# CRCP0_1.0 register map
Vendor: Texas Instruments
Peripheral module from a debugger description file (folder mspm0gx218_gx207).
Registers are 32-bit, read-write, no defined reset value unless marked. A register's access mark holds for its fields unless they carry their own. Offsets are as the file gives them; lines under a group give offsets from that group; [hi:lo] are bit positions; {n}, {i} and the like mark numbered series; 'fields as' and 'values as' point back to an identical list; <NAME> marks a mode.

## CRCP0
0x800 CRCP0_GPRCM group
  0x00 CRCP0_PWREN — Power enable
    [0] ENABLE — Enable the power
      0=DISABLE (Disable Power); 1=ENABLE (Enable Power)
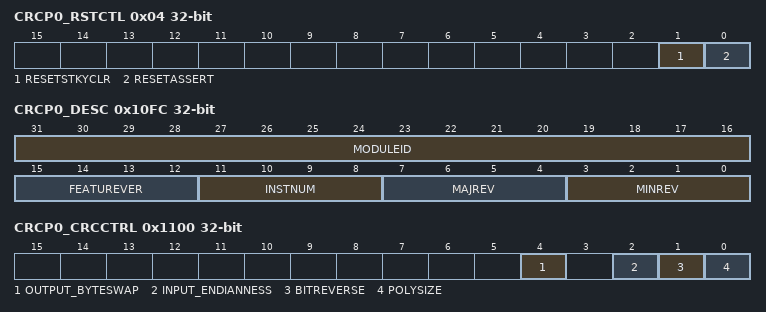
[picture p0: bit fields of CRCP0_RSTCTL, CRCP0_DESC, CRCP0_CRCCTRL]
  0x04 CRCP0_RSTCTL — Reset Control
    [1] RESETSTKYCLR — Clear the RESETSTKY bit in the STAT register
      0=NOP (Writing 0 has no effect); 1=CLR (Clear reset sticky bit)
    [0] RESETASSERT — Assert reset to the peripheral
      0=NOP (Writing 0 has no effect); 1=ASSERT (Assert reset)
  0x14 CRCP0_STAT ro — Status Register
    [16] RESETSTKY — This bit indicates, if the peripheral was reset, since this bit was cleared by RESETSTKYCLR in the RSTCTL register
      0=NORES (The peripheral has not been reset since this bit was last cleared by RESETSTKYCLR in the RSTCTL register); 1=RESET (The peripheral was reset since the last bit clear)
0x1004 CRCP0_CLKSEL ro — Clock Select
  [0] MCLK_SEL — Selects main clock (MCLK) if enabled
    0=DISABLE (Does not select this clock as a source); 1=ENABLE (Select this clock as a source)
0x10FC CRCP0_DESC — Module Description
  [31:16] MODULEID — Module identification contains a unique peripheral identification number. The assignments are maintained in a central database for all of the platform modules to ensure uniqueness.
    0=MINIMUM (Smallest value); 0xFFFF=MAXIMUM (Highest possible value)
  [15:12] FEATUREVER — Feature Set for the module *instance*
    0=MINIMUM (Smallest value); 15=MAXIMUM (Highest possible value)
  [11:8] INSTNUM — Instance Number within the device. This will be a parameter to the RTL for modules that can have multiple instances
    values as FEATUREVER
  [7:4] MAJREV — Major rev of the IP
    values as FEATUREVER
  [3:0] MINREV — Minor rev of the IP
    values as FEATUREVER
0x1100 CRCP0_CRCCTRL — CRC Control Register
  [4] OUTPUT_BYTESWAP — CRC Output Byteswap Enable. This bit controls whether the output is byte-swapped upon a read of the CRCOUT register. If CRCOUT is accessed as a half-word, and the OUTPUT_BYTESWAP is set to to 1, then the two bytes in the 16-bit access are swapped and returned. B1 is returned as B0 B0 is returned as B1 If CRCOUT is accessed as a word, and the OUTPUT_BYTESWAP is set to 1, then the four bytes in the 32-bit read are swapped. B3 is returned as B0 B2 is returned as B1 B1 is returned as B2 B0 is returned as B3 Note that if the CRC POLYSIZE is 16-bit and a 32-bit read of CRCOUT is performed with OUTPUT_BYTESWAP enabled, then the output is: MSB LSB 0x0 0x0 B0 B1 If the CRC POLYSIZE is 16-bit and a 32-bit read of CRCOUT is performed with OUTPUT_BYTESWAP disabled, then the output is: MSB LSB 0x0 0x0 B1 B0
    0=DISABLE (Output byteswapping is disabled); 1=ENABLE (Output byteswapping is enabled.)
  [2] INPUT_ENDIANNESS — CRC Endian. This bit indicates the byte order within a word or half word of input data.
    0=LITTLE_ENDIAN (LSB is lowest memory address and first to be processed.); 1=BIG_ENDIAN (LSB is highest memory address and last to be processed.)
  [1] BITREVERSE — CRC Bit Input and output Reverse. This bit indictes that the bit order of each input byte used for the CRC calculation is reversed before it is passed to the generator, and that the bit order of the calculated CRC is be reversed when read from CRC_RESULT.
    0=NOT_REVERSED (Bit order is not reversed.); 1=REVERSED (Bit order is reversed.)
  [0] POLYSIZE — This bit indicates which CRC calculation is performed by the generator.
    0=CRC32 (CRC-32 ISO-3309 calulation is performed); 1=CRC16 (CRC-16 CCITT is performed)
0x1104 CRCP0_CRCSEED — CRC Seed Register
  [31:0] SEED — Seed Data
    0=MINIMUM (Mnimum value); 0xFFFFFFFF=MAXIMUM (Maximum value)
0x1108 CRCP0_CRCIN — CRC Input Data Register
  [31:0] DATA — Input Data
    0=MINIMUM (Mnimum value); 0xFFFFFFFF=MAXIMUM (Maximum value)
0x110C CRCP0_CRCOUT ro — CRC Output Result Register
  [31:0] RESULT
    0=MINIMUM (Mnimum value); 0xFFFFFFFF=MAXIMUM (Maximum value)
0x1110 CRCP0_CRCPOLY access not given — CRC Polynomial configuration register
{0x1800+4i} CRCP0_CRCIN_IDX[{i}] (i=0..511) — CRC Input Data Array Register
  [31:0] DATA — Input Data
    0=MINIMUM (Minimum value); 0xFFFFFFFF=MAXIMUM (Maximum value)
